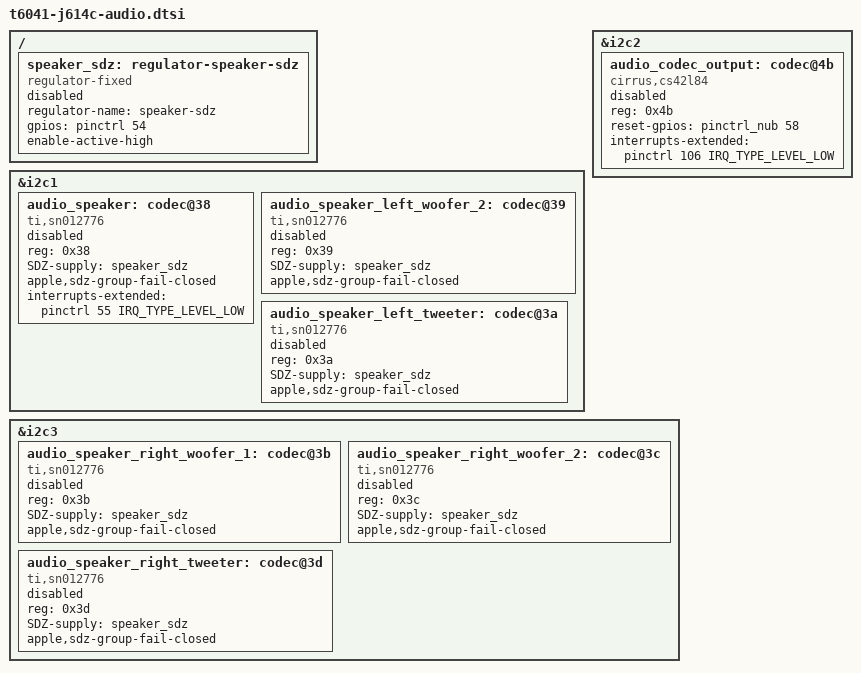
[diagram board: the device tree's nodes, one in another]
// SPDX-License-Identifier: GPL-2.0+ OR MIT
/* J614C audio endpoints. Keep the routes and hardware disabled until qualified. */

#include <dt-bindings/gpio/gpio.h>
#include <dt-bindings/interrupt-controller/irq.h>

/ {
	speaker_sdz: regulator-speaker-sdz {
		compatible = "regulator-fixed";
		regulator-name = "speaker-sdz";
		gpios = <&pinctrl 54 GPIO_ACTIVE_HIGH>;
		enable-active-high;
		status = "disabled";
	};
};

&i2c1 {
	audio_speaker: codec@38 {
		compatible = "ti,sn012776", "ti,tas2764";
		reg = <0x38>;
		#sound-dai-cells = <0>;
		SDZ-supply = <&speaker_sdz>;
		apple,sdz-group-fail-closed;
		interrupts-extended = <&pinctrl 55 IRQ_TYPE_LEVEL_LOW>;
		status = "disabled";
	};

	audio_speaker_left_woofer_2: codec@39 {
		compatible = "ti,sn012776", "ti,tas2764";
		reg = <0x39>;
		#sound-dai-cells = <0>;
		SDZ-supply = <&speaker_sdz>;
		apple,sdz-group-fail-closed;
		status = "disabled";
	};

	audio_speaker_left_tweeter: codec@3a {
		compatible = "ti,sn012776", "ti,tas2764";
		reg = <0x3a>;
		#sound-dai-cells = <0>;
		SDZ-supply = <&speaker_sdz>;
		apple,sdz-group-fail-closed;
		status = "disabled";
	};

};

&i2c2 {
	audio_codec_output: codec@4b {
		compatible = "cirrus,cs42l84";
		reg = <0x4b>;
		#sound-dai-cells = <0>;
		reset-gpios = <&pinctrl_nub 58 GPIO_ACTIVE_HIGH>;
		interrupts-extended = <&pinctrl 106 IRQ_TYPE_LEVEL_LOW>;
		status = "disabled";
	};

};

&i2c3 {
	audio_speaker_right_woofer_1: codec@3b {
		compatible = "ti,sn012776", "ti,tas2764";
		reg = <0x3b>;
		#sound-dai-cells = <0>;
		SDZ-supply = <&speaker_sdz>;
		apple,sdz-group-fail-closed;
		status = "disabled";
	};

	audio_speaker_right_woofer_2: codec@3c {
		compatible = "ti,sn012776", "ti,tas2764";
		reg = <0x3c>;
		#sound-dai-cells = <0>;
		SDZ-supply = <&speaker_sdz>;
		apple,sdz-group-fail-closed;
		status = "disabled";
	};

	audio_speaker_right_tweeter: codec@3d {
		compatible = "ti,sn012776", "ti,tas2764";
		reg = <0x3d>;
		#sound-dai-cells = <0>;
		SDZ-supply = <&speaker_sdz>;
		apple,sdz-group-fail-closed;
		status = "disabled";
	};

};
